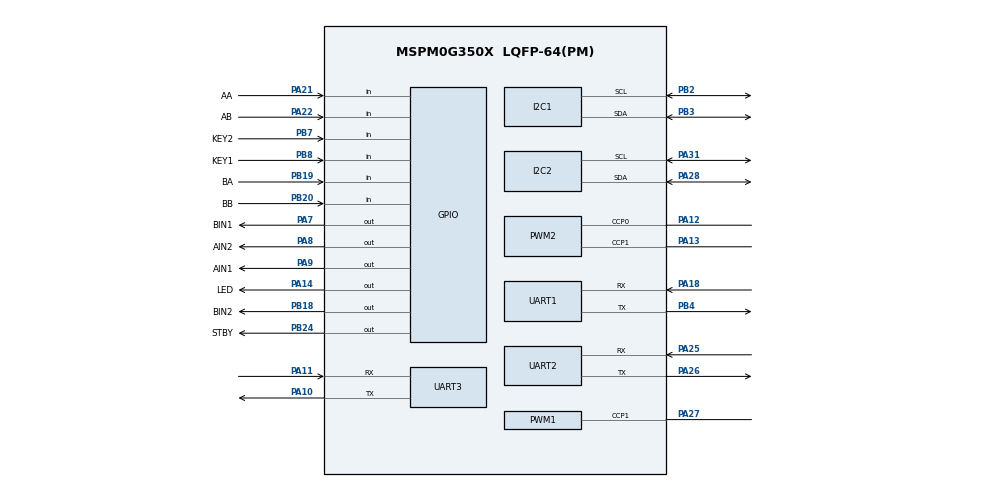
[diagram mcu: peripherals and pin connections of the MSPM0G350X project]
/**
 * @cliArgs --device "MSPM0G350X" --part "Default" --package "LQFP-64(PM)" --product "mspm0_sdk@2.10.00.04"
 * @versions {"tool":"1.26.2+4477"}
 */

/**
 * Import the modules used in this configuration.
 */
const ADC12  = scripting.addModule("/ti/driverlib/ADC12", {}, false);
const ADC121 = ADC12.addInstance();
const GPIO   = scripting.addModule("/ti/driverlib/GPIO", {}, false);
const GPIO1  = GPIO.addInstance();
const GPIO2  = GPIO.addInstance();
const GPIO3  = GPIO.addInstance();
const I2C    = scripting.addModule("/ti/driverlib/I2C", {}, false);
const I2C1   = I2C.addInstance();
const I2C2   = I2C.addInstance();
const PWM    = scripting.addModule("/ti/driverlib/PWM", {}, false);
const PWM1   = PWM.addInstance();
const PWM2   = PWM.addInstance();
const SYSCTL = scripting.addModule("/ti/driverlib/SYSCTL");
const TIMER  = scripting.addModule("/ti/driverlib/TIMER", {}, false);
const TIMER1 = TIMER.addInstance();
const TIMER2 = TIMER.addInstance();
const UART   = scripting.addModule("/ti/driverlib/UART", {}, false);
const UART1  = UART.addInstance();
const UART2  = UART.addInstance();
const UART3  = UART.addInstance();
const VREF   = scripting.addModule("/ti/driverlib/VREF");

/**
 * Write custom configuration values to the imported modules.
 */
const divider9       = system.clockTree["UDIV"];
divider9.divideValue = 2;

const gate7  = system.clockTree["MFCLKGATE"];
gate7.enable = true;

const multiplier2         = system.clockTree["PLL_QDIV"];
multiplier2.multiplyValue = 5;

const mux4       = system.clockTree["EXHFMUX"];
mux4.inputSelect = "EXHFMUX_XTAL";

const mux8       = system.clockTree["HSCLKMUX"];
mux8.inputSelect = "HSCLKMUX_SYSPLL0";

const pinFunction4     = system.clockTree["HFXT"];
pinFunction4.inputFreq = 40;
pinFunction4.enable    = true;

ADC121.$name                      = "xuanniu";
ADC121.adcMem0vref                = "VREF";
ADC121.adcMem0chansel             = "DL_ADC12_INPUT_CHAN_1";
ADC121.repeatMode                 = true;
ADC121.peripheral.adcPin1.$assign = "PA16";
ADC121.adcPin1Config.$name        = "ti_driverlib_gpio_GPIOPinGeneric4";

const Board = scripting.addModule("/ti/driverlib/Board", {}, false);

GPIO1.$name                         = "LED_BEEP";
GPIO1.associatedPins[0].$name       = "LED";
GPIO1.associatedPins[0].pin.$assign = "PA14";

GPIO2.$name                              = "KEY";
GPIO2.associatedPins.create(2);
GPIO2.associatedPins[0].direction        = "INPUT";
GPIO2.associatedPins[0].internalResistor = "PULL_DOWN";
GPIO2.associatedPins[0].polarity         = "RISE";
GPIO2.associatedPins[0].$name            = "KEY1";
GPIO2.associatedPins[0].pin.$assign      = "PB8";
GPIO2.associatedPins[1].direction        = "INPUT";
GPIO2.associatedPins[1].internalResistor = "PULL_DOWN";
GPIO2.associatedPins[1].polarity         = "RISE";
GPIO2.associatedPins[1].$name            = "KEY2";
GPIO2.associatedPins[1].pin.$assign      = "PB7";

GPIO3.$name                              = "DC_MOTOR";
GPIO3.associatedPins.create(9);
GPIO3.associatedPins[0].$name            = "AIN2";
GPIO3.associatedPins[0].pin.$assign      = "PA8";
GPIO3.associatedPins[1].$name            = "AIN1";
GPIO3.associatedPins[1].pin.$assign      = "PA9";
GPIO3.associatedPins[2].$name            = "STBY";
GPIO3.associatedPins[2].pin.$assign      = "PB24";
GPIO3.associatedPins[3].$name            = "AA";
GPIO3.associatedPins[3].direction        = "INPUT";
GPIO3.associatedPins[3].interruptEn      = true;
GPIO3.associatedPins[3].polarity         = "RISE_FALL";
GPIO3.associatedPins[3].internalResistor = "PULL_DOWN";
GPIO3.associatedPins[3].pin.$assign      = "PA21";
GPIO3.associatedPins[4].$name            = "AB";
GPIO3.associatedPins[4].direction        = "INPUT";
GPIO3.associatedPins[4].interruptEn      = true;
GPIO3.associatedPins[4].polarity         = "RISE_FALL";
GPIO3.associatedPins[4].internalResistor = "PULL_DOWN";
GPIO3.associatedPins[4].pin.$assign      = "PA22";
GPIO3.associatedPins[5].$name            = "BIN2";
GPIO3.associatedPins[5].pin.$assign      = "PB18";
GPIO3.associatedPins[6].$name            = "BIN1";
GPIO3.associatedPins[6].pin.$assign      = "PA7";
GPIO3.associatedPins[7].$name            = "BA";
GPIO3.associatedPins[7].direction        = "INPUT";
GPIO3.associatedPins[7].interruptEn      = true;
GPIO3.associatedPins[7].polarity         = "RISE_FALL";
GPIO3.associatedPins[7].internalResistor = "PULL_DOWN";
GPIO3.associatedPins[7].pin.$assign      = "PB19";
GPIO3.associatedPins[8].$name            = "BB";
GPIO3.associatedPins[8].direction        = "INPUT";
GPIO3.associatedPins[8].interruptEn      = true;
GPIO3.associatedPins[8].polarity         = "RISE_FALL";
GPIO3.associatedPins[8].internalResistor = "PULL_DOWN";
GPIO3.associatedPins[8].pin.$assign      = "PB20";

I2C1.$name                             = "OLED";
I2C1.basicEnableController             = true;
I2C1.advDigitalGlitchFilter            = "CLOCKS_1";
I2C1.advControllerRXFIFOTRIG           = "BYTES_8";
I2C1.advControllerTXFIFOTRIG           = "BYTES_7";
I2C1.enableDMAEvent1                   = false;
I2C1.enableDMAEvent2                   = false;
I2C1.peripheral.$assign                = "I2C1";
I2C1.peripheral.sdaPin.$assign         = "PB3";
I2C1.peripheral.sclPin.$assign         = "PB2";
I2C1.sdaPinConfig.hideOutputInversion  = scripting.forceWrite(false);
I2C1.sdaPinConfig.onlyInternalResistor = scripting.forceWrite(false);
I2C1.sdaPinConfig.passedPeripheralType = scripting.forceWrite("Digital");
I2C1.sdaPinConfig.$name                = "ti_driverlib_gpio_GPIOPinGeneric0";
I2C1.sdaPinConfig.enableConfig         = true;
I2C1.sdaPinConfig.internalResistor     = "PULL_UP";
I2C1.sclPinConfig.hideOutputInversion  = scripting.forceWrite(false);
I2C1.sclPinConfig.onlyInternalResistor = scripting.forceWrite(false);
I2C1.sclPinConfig.passedPeripheralType = scripting.forceWrite("Digital");
I2C1.sclPinConfig.$name                = "ti_driverlib_gpio_GPIOPinGeneric1";
I2C1.sclPinConfig.enableConfig         = true;
I2C1.sclPinConfig.internalResistor     = "PULL_UP";

I2C2.$name                             = "eight_road";
I2C2.basicEnableController             = true;
I2C2.advDigitalGlitchFilter            = "CLOCKS_1";
I2C2.advControllerTXFIFOTRIG           = "BYTES_1";
I2C2.enableDMAEvent1                   = false;
I2C2.enableDMAEvent2                   = false;
I2C2.peripheral.$assign                = "I2C0";
I2C2.peripheral.sdaPin.$assign         = "PA28";
I2C2.peripheral.sclPin.$assign         = "PA31";
I2C2.sdaPinConfig.hideOutputInversion  = scripting.forceWrite(false);
I2C2.sdaPinConfig.onlyInternalResistor = scripting.forceWrite(false);
I2C2.sdaPinConfig.passedPeripheralType = scripting.forceWrite("Digital");
I2C2.sdaPinConfig.$name                = "ti_driverlib_gpio_GPIOPinGeneric13";
I2C2.sdaPinConfig.enableConfig         = true;
I2C2.sdaPinConfig.internalResistor     = "PULL_UP";
I2C2.sclPinConfig.hideOutputInversion  = scripting.forceWrite(false);
I2C2.sclPinConfig.onlyInternalResistor = scripting.forceWrite(false);
I2C2.sclPinConfig.passedPeripheralType = scripting.forceWrite("Digital");
I2C2.sclPinConfig.$name                = "ti_driverlib_gpio_GPIOPinGeneric14";
I2C2.sclPinConfig.enableConfig         = true;
I2C2.sclPinConfig.internalResistor     = "PULL_UP";

PWM1.$name                              = "SERVO";
PWM1.clockDivider                       = 8;
PWM1.clockPrescale                      = 100;
PWM1.pwmMode                            = "EDGE_ALIGN_UP";
PWM1.ccIndex                            = [1];
PWM1.timerCount                         = 2000;
PWM1.timerStartTimer                    = true;
PWM1.ccp1PinConfig.direction            = scripting.forceWrite("OUTPUT");
PWM1.ccp1PinConfig.hideOutputInversion  = scripting.forceWrite(false);
PWM1.ccp1PinConfig.onlyInternalResistor = scripting.forceWrite(false);
PWM1.ccp1PinConfig.passedPeripheralType = scripting.forceWrite("Digital");
PWM1.ccp1PinConfig.$name                = "ti_driverlib_gpio_GPIOPinGeneric7";
PWM1.peripheral.$assign                 = "TIMG7";
PWM1.peripheral.ccp1Pin.$assign         = "PA27";
PWM1.PWM_CHANNEL_1.$name                = "ti_driverlib_pwm_PWMTimerCC0";
PWM1.PWM_CHANNEL_1.dutyCycle            = 7.5;

PWM2.timerStartTimer                    = true;
PWM2.timerCount                         = 4000;
PWM2.pwmMode                            = "EDGE_ALIGN_UP";
PWM2.$name                              = "PWMAB";
PWM2.peripheral.$assign                 = "TIMG0";
PWM2.peripheral.ccp0Pin.$assign         = "PA12";
PWM2.peripheral.ccp1Pin.$assign         = "PA13";
PWM2.PWM_CHANNEL_0.$name                = "ti_driverlib_pwm_PWMTimerCC1";
PWM2.PWM_CHANNEL_1.$name                = "ti_driverlib_pwm_PWMTimerCC2";
PWM2.ccp0PinConfig.direction            = scripting.forceWrite("OUTPUT");
PWM2.ccp0PinConfig.hideOutputInversion  = scripting.forceWrite(false);
PWM2.ccp0PinConfig.onlyInternalResistor = scripting.forceWrite(false);
PWM2.ccp0PinConfig.passedPeripheralType = scripting.forceWrite("Digital");
PWM2.ccp0PinConfig.$name                = "ti_driverlib_gpio_GPIOPinGeneric6";
PWM2.ccp1PinConfig.$name                = "ti_driverlib_gpio_GPIOPinGeneric8";
PWM2.ccp1PinConfig.direction            = scripting.forceWrite("OUTPUT");
PWM2.ccp1PinConfig.hideOutputInversion  = scripting.forceWrite(false);
PWM2.ccp1PinConfig.onlyInternalResistor = scripting.forceWrite(false);
PWM2.ccp1PinConfig.passedPeripheralType = scripting.forceWrite("Digital");

SYSCTL.forceDefaultClkConfig = true;
SYSCTL.clockTreeEn           = true;

TIMER1.$name              = "MOTOR_PID";
TIMER1.timerMode          = "PERIODIC_UP";
TIMER1.timerClkPrescale   = 100;
TIMER1.interrupts         = ["LOAD"];
TIMER1.timerPeriod        = "10ms";
TIMER1.peripheral.$assign = "TIMA0";

TIMER2.$name              = "NTB";
TIMER2.timerClkDiv        = 8;
TIMER2.timerMode          = "PERIODIC_UP";
TIMER2.timerClkSrc        = "MFCLK";
TIMER2.timerStartTimer    = true;
TIMER2.timerPeriod        = "6000 s";
TIMER2.peripheral.$assign = "TIMG12";

UART1.targetBaudRate                   = 115200;
UART1.enabledInterrupts                = ["RX"];
UART1.$name                            = "K230";
UART1.peripheral.$assign               = "UART1";
UART1.peripheral.rxPin.$assign         = "PA18";
UART1.peripheral.txPin.$assign         = "PB4";
UART1.txPinConfig.direction            = scripting.forceWrite("OUTPUT");
UART1.txPinConfig.hideOutputInversion  = scripting.forceWrite(false);
UART1.txPinConfig.onlyInternalResistor = scripting.forceWrite(false);
UART1.txPinConfig.passedPeripheralType = scripting.forceWrite("Digital");
UART1.txPinConfig.$name                = "ti_driverlib_gpio_GPIOPinGeneric2";
UART1.rxPinConfig.hideOutputInversion  = scripting.forceWrite(false);
UART1.rxPinConfig.onlyInternalResistor = scripting.forceWrite(false);
UART1.rxPinConfig.passedPeripheralType = scripting.forceWrite("Digital");
UART1.rxPinConfig.$name                = "ti_driverlib_gpio_GPIOPinGeneric3";

UART2.$name                            = "IMU601";
UART2.targetBaudRate                   = 115200;
UART2.enabledInterrupts                = ["RX"];
UART2.peripheral.$assign               = "UART3";
UART2.peripheral.rxPin.$assign         = "PA25";
UART2.peripheral.txPin.$assign         = "PA26";
UART2.txPinConfig.direction            = scripting.forceWrite("OUTPUT");
UART2.txPinConfig.hideOutputInversion  = scripting.forceWrite(false);
UART2.txPinConfig.onlyInternalResistor = scripting.forceWrite(false);
UART2.txPinConfig.passedPeripheralType = scripting.forceWrite("Digital");
UART2.txPinConfig.$name                = "ti_driverlib_gpio_GPIOPinGeneric9";
UART2.rxPinConfig.hideOutputInversion  = scripting.forceWrite(false);
UART2.rxPinConfig.onlyInternalResistor = scripting.forceWrite(false);
UART2.rxPinConfig.passedPeripheralType = scripting.forceWrite("Digital");
UART2.rxPinConfig.$name                = "ti_driverlib_gpio_GPIOPinGeneric10";

UART3.targetBaudRate                   = 115200;
UART3.enabledInterrupts                = ["RX"];
UART3.$name                            = "DEBUG";
UART3.peripheral.$assign               = "UART0";
UART3.peripheral.rxPin.$assign         = "PA11";
UART3.peripheral.txPin.$assign         = "PA10";
UART3.txPinConfig.direction            = scripting.forceWrite("OUTPUT");
UART3.txPinConfig.hideOutputInversion  = scripting.forceWrite(false);
UART3.txPinConfig.onlyInternalResistor = scripting.forceWrite(false);
UART3.txPinConfig.passedPeripheralType = scripting.forceWrite("Digital");
UART3.txPinConfig.$name                = "ti_driverlib_gpio_GPIOPinGeneric11";
UART3.rxPinConfig.hideOutputInversion  = scripting.forceWrite(false);
UART3.rxPinConfig.onlyInternalResistor = scripting.forceWrite(false);
UART3.rxPinConfig.passedPeripheralType = scripting.forceWrite("Digital");
UART3.rxPinConfig.$name                = "ti_driverlib_gpio_GPIOPinGeneric12";

VREF.basicIntVolt           = "DL_VREF_BUFCONFIG_OUTPUT_2_5V";
VREF.profile                = "INT_2_5_V";
VREF.vrefPosPinConfig.$name = "ti_driverlib_gpio_GPIOPinGeneric5";

/**
 * Pinmux solution for unlocked pins/peripherals. This ensures that minor changes to the automatic solver in a future
 * version of the tool will not impact the pinmux you originally saw.  These lines can be completely deleted in order to
 * re-solve from scratch.
 */
pinFunction4.peripheral.$suggestSolution           = "SYSCTL";
pinFunction4.peripheral.hfxInPin.$suggestSolution  = "PA5";
pinFunction4.peripheral.hfxOutPin.$suggestSolution = "PA6";
ADC121.peripheral.$suggestSolution                 = "ADC1";
Board.peripheral.$suggestSolution                  = "DEBUGSS";
Board.peripheral.swclkPin.$suggestSolution         = "PA20";
Board.peripheral.swdioPin.$suggestSolution         = "PA19";
VREF.peripheral.$suggestSolution                   = "VREF";
VREF.peripheral.vrefPosPin.$suggestSolution        = "PA23";
